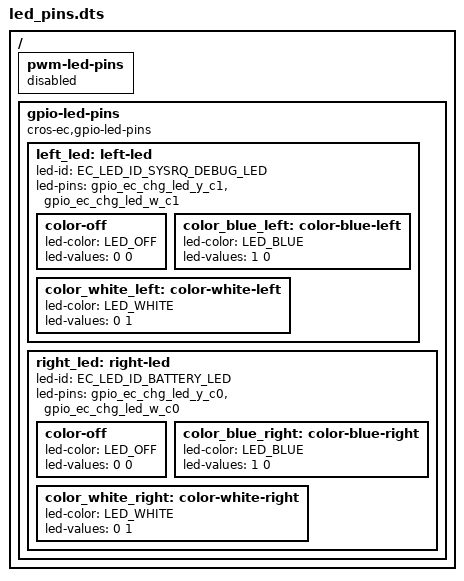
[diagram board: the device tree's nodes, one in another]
/* Copyright 2022 The ChromiumOS Authors
 * Use of this source code is governed by a BSD-style license that can be
 * found in the LICENSE file.
 */

 /* Based off of `ec/zephyr/program/herobrine/led_pins_herobrine.dts`
  * Modified led-colors to obtain better test coverage.
  */
/ {
	pwm-led-pins {
		status = "disabled";
	};

	gpio-led-pins {
		compatible = "cros-ec,gpio-led-pins";

		left_led: left-led {
			led-id = "EC_LED_ID_SYSRQ_DEBUG_LED";
			led-pins = <&gpio_ec_chg_led_y_c1
				    &gpio_ec_chg_led_w_c1>;

			color-off {
				led-color = "LED_OFF";
				led-values = <0 0>;
			};

			color_blue_left: color-blue-left {
				led-color = "LED_BLUE";
				led-values = <1 0>;
			};
			color_white_left: color-white-left {
				led-color = "LED_WHITE";
				led-values = <0 1>;
			};
		};

		right_led: right-led {
			led-id = "EC_LED_ID_BATTERY_LED";
			led-pins = <&gpio_ec_chg_led_y_c0
				    &gpio_ec_chg_led_w_c0>;

			color-off {
				led-color = "LED_OFF";
				led-values = <0 0>;
			};
			color_blue_right: color-blue-right {
				led-color = "LED_BLUE";
				led-values = <1 0>;
			};
			color_white_right: color-white-right {
				led-color = "LED_WHITE";
				led-values = <0 1>;
			};
		};
	};
};
